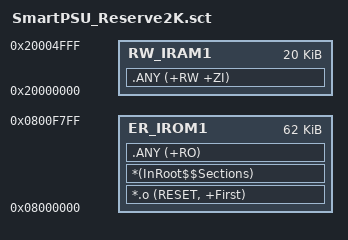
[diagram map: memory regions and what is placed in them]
; STM32F103C8 64KB Flash / 20KB SRAM. Reserve last 2 x 1KB pages.
; Application image: 0x08000000 .. 0x0800F7FF (62KB).
; Settings pages: 0x0800F800 and 0x0800FC00.
LR_IROM1 0x08000000 0x0000F800  {
  ER_IROM1 0x08000000 0x0000F800  {
    *.o (RESET, +First)
    *(InRoot$$Sections)
    .ANY (+RO)
  }
  RW_IRAM1 0x20000000 0x00005000  {
    .ANY (+RW +ZI)
  }
}
